# GD32A72_A74x register map
File version: 1.0
CPU: CM7 r2p1, little endian, MPU, FPU, DSP, 4 interrupt priority bits
Registers are 32-bit, read-write, reset 0x0 unless marked. A register's access mark holds for its fields unless they carry their own. Offsets are from the block's base; [hi:lo] are bit positions; {n}, {i} and the like mark numbered series; 'fields as' and 'values as' point back to an identical list.

## ENET_DMA — ENET_DMA DMA
Base 0x4000B000
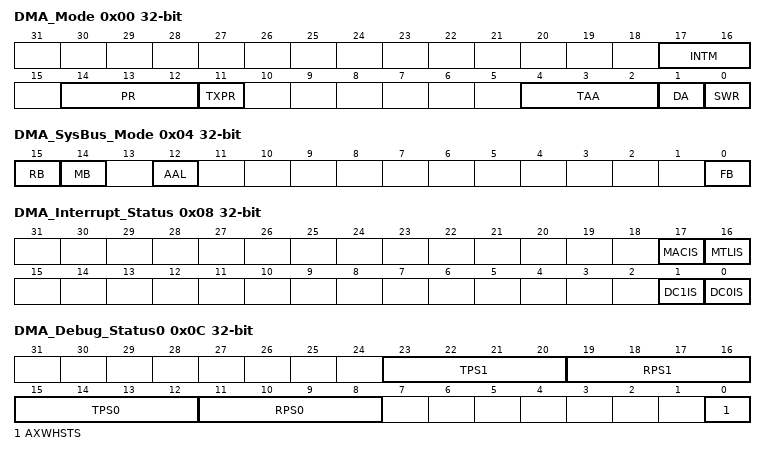
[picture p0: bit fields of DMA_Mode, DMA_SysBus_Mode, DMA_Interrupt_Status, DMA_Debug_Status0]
0x00 DMA_Mode
  [17:16] INTM — Interrupt Mode
    0=MODE0 (See above description); 1=MODE1 (See above description); 2=MODE2 (See above description)
  [14:12] PR — Priority Ratio
    {v}=R_{v+1}_1 (The priority ratio is {v+1}:1) (v=0..7)
  [11] TXPR — Transmit Priority
    0=DISABLE (Disabled); 1=ENABLE (Enabled)
  [4:2] TAA — Transmit Arbitration Algorithm
    0=FP (Fixed priority (Channel 0 has the lowest priority and the last channel has the highest priority)); 1=WSP (Weighted Strict Priority (WSP)); 2=WRR (Weighted Round-Robin (WRR))
  [1] DA — DMA Tx or Rx Arbitration Scheme
    0=WRR (Weighted Round-Robin with Rx:Tx or Tx:Rx); 1=FP (Fixed Priority)
  [0] SWR — Software Reset
    0=DISABLE (Disabled); 1=ENABLE (Enabled)
0x04 DMA_SysBus_Mode — DMA System Bus Mode
  [all] fields
    0=DISABLE (Disabled); 1=ENABLE (Enabled)
  [15] RB — Rebuild INCRx Burst
  [14] MB — Mixed Burst
  [12] AAL — Address-Aligned Beats
  [0] FB — Fixed Burst Length
0x08 DMA_Interrupt_Status ro
  [all] fields
    0=INACTIVE (Not detected); 1=ACTIVE (Detected)
  [17] MACIS — MAC Interrupt Status
  [16] MTLIS — MTL Interrupt Status
  [1] DC1IS — DMA Channel 1 Interrupt Status
  [0] DC0IS — DMA Channel 0 Interrupt Status
0x0C DMA_Debug_Status0 ro
  [23:20] TPS1 — DMA Channel 1 Transmit Process State
    0=STOP (Stopped (Reset or stop transmit command issued)); 1=RUN_FTTD (Running (Fetching transmit transfer descriptor)); 2=RUN_WS (Running (Waiting for status)); 3=RUN_RDS (Running (Reading data from system memory buffer and queuing it to the transmit buffer (Tx FIFO))); 4=TSTMP_WS (Timestamp write state); 6=SUSPND (Suspended (Transmit descriptor unavailable or transmit buffer underflow)); 7=RUN_CTD (Running (Closing transmit descriptor))
  [19:16] RPS1 — DMA Channel 1 Receive Process State
    0=STOP (Stopped (Reset or Stop receive command issued)); 1=RUN_FRTD (Running (Fetching receive transfer descriptor)); 3=RUN_WRP (Running (Waiting for receive packet)); 4=SUSPND (Suspended (Receive descriptor unavailable)); 5=RUN_CRD (Running (Closing the receive descriptor)); 6=TSTMP (Timestamp write state); 7=RUN_TRP (Running (Transferring the received packet data from the receive buffer to the system memory))
  [15:12] TPS0 — DMA Channel 0 Transmit Process State
    values as TPS1
  [11:8] RPS0 — DMA Channel 0 Receive Process State
    0=STOP (Stopped (Reset or stop receive command issued)); 1=RUN_FRTD (Running (Fetching receive transfer descriptor)); 3=RUN_WRP (Running (Waiting for receive packet)); 4=SUSPND (Suspended (Receive descriptor unavailable)); 5=RUN_CRD (Running (Closing the receive descriptor)); 6=TSTMP (Timestamp write state); 7=RUN_TRP (Running (Transferring the received packet data from the receive buffer to the system memory))
  [0] AXWHSTS — AHB Master Status
    0=INACTIVE (Not detected); 1=ACTIVE (detected)
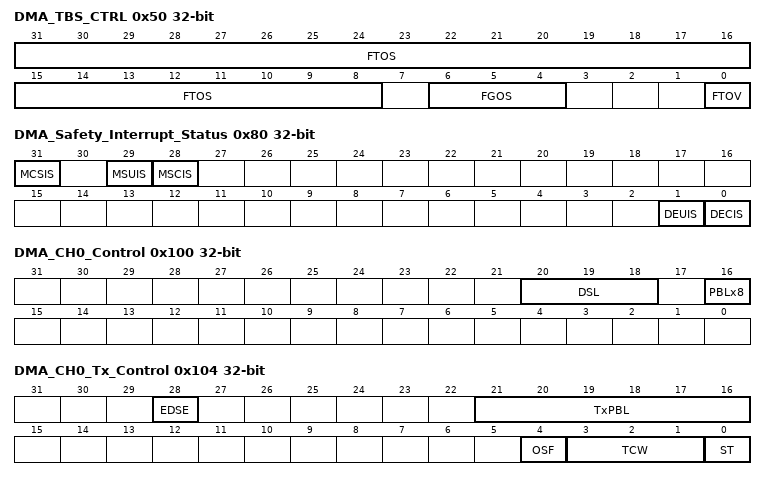
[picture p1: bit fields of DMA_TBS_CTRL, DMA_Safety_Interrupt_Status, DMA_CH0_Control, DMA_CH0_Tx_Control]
0x50 DMA_TBS_CTRL — DMA TBS Control
  [31:8] FTOS — Fetch Time Offset
  [6:4] FGOS — Fetch GSN Offset
  [0] FTOV — Fetch Time Offset Valid
    0=INVALID; 1=VALID
0x80 DMA_Safety_Interrupt_Status ro
  [all] fields
    0=INACTIVE (Not detected); 1=ACTIVE (Detected)
  [31] MCSIS — MAC Safety Uncorrectable Interrupt Status
  [29] MSUIS — MTL Safety Uncorrectable Error Interrupt Status
  [28] MSCIS — MTL Safety Correctable Error Interrupt Status
  [1] DEUIS — DMA ECC Uncorrectable Error Interrupt Status
  [0] DECIS — DMA ECC Correctable Error Interrupt Status
0x100 DMA_CH0_Control — DMA Channel 0 Control
  [20:18] DSL — Descriptor Skip Length
  [16] PBLx8 — 8xPBL mode
    0=DISABLE (Disabled); 1=ENABLE (Enabled)
0x104 DMA_CH0_Tx_Control — DMA Channel Tx Control
  [28] EDSE — Enhanced Descriptor Enable
    0=DISABLE (Disabled); 1=ENABLE (Enabled)
  [21:16] TxPBL — Transmit Programmable Burst Length
  [4] OSF — Operate on Second Packet
    0=DISABLE (Disabled); 1=ENABLE (Enabled)
  [3:1] TCW — Transmit Channel Weight
  [0] ST — Start or Stop Transmission Command
    0=STOP; 1=START
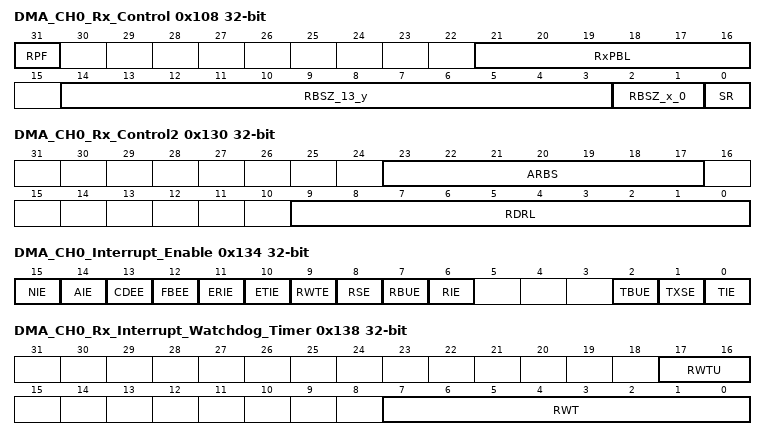
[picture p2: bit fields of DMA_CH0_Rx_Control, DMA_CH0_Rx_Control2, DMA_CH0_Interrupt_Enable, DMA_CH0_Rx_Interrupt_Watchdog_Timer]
0x108 DMA_CH0_Rx_Control — DMA Channel Rx Control
  [31] RPF — Rx Packet Flush
    0=DISABLE (Disabled); 1=ENABLE (Enabled)
  [21:16] RxPBL — Receive Programmable Burst Length
  [14:3] RBSZ_13_y — Receive Buffer size High
  [2:1] RBSZ_x_0 ro — Receive Buffer size Low
  [0] SR — Start or Stop Receive
    0=STOP; 1=START
0x114 DMA_CH0_TxDesc_Address — DMA Channel 0 Tx Descriptor List Address
  [31:2] TDESLA — Start of Transmit List
0x11C DMA_CH0_RxDesc_Address — DMA Channel 0 Rx Descriptor List Address
  [31:2] RDESLA — Start of Receive List
0x120 DMA_CH0_TxDesc_Tail_Pointer — DMA Channel 0 Tx Descriptor Tail Pointer
  [31:2] TDTP — Transmit Descriptor Tail Pointer
0x128 DMA_CH0_RxDesc_Tail_Pointer — DMA Channeli 0 Rx Descriptor List Pointer
  [31:2] RDTP — Receive Descriptor Tail Pointer
0x12C DMA_CH0_TxDesc_Ring_Length — DMA Channel 0 Tx Descriptor Ring Length
  [9:0] TDRL — Transmit Descriptor Ring Length
0x130 DMA_CH0_Rx_Control2 — DMA channel receive control 2 register
  [23:17] ARBS — Alternate Receive Buffer Size
  [9:0] RDRL — Receive Descriptor Ring Length
0x134 DMA_CH0_Interrupt_Enable — DMA Channel 0 Interrupt Enable
  [all] fields
    0=DISABLE; 1=ENABLE
  [15] NIE — Normal Interrupt Summary Enable
  [14] AIE — Abnormal Interrupt Summary Enable
  [13] CDEE — Context Descriptor Error Enable
  [12] FBEE — Fatal Bus Error Enable
  [11] ERIE — Early Receive Interrupt Enable
  [10] ETIE — Early Transmit Interrupt Enable
  [9] RWTE — Receive Watchdog Timeout Enable
  [8] RSE — Receive Stopped Enable
  [7] RBUE — Receive Buffer Unavailable Enable
  [6] RIE — Receive Interrupt Enable
  [2] TBUE — Transmit Buffer Unavailable Enable
  [1] TXSE — Transmit Stopped Enable
  [0] TIE — Transmit Interrupt Enable
0x138 DMA_CH0_Rx_Interrupt_Watchdog_Timer — DMA Channel 0 Rx Interrupt Watchdog Timer
  [17:16] RWTU — Receive Interrupt Watchdog Timer Count Units
  [7:0] RWT — Receive Interrupt Watchdog Timer Count
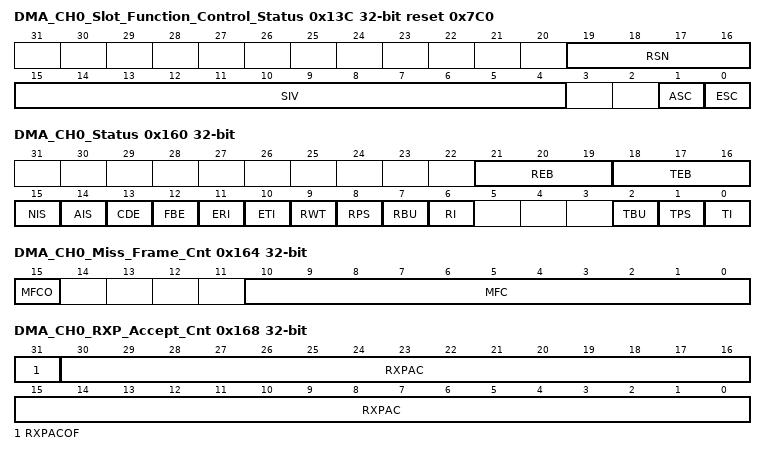
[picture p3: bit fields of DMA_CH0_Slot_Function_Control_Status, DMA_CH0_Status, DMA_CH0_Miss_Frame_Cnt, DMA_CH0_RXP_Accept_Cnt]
0x13C DMA_CH0_Slot_Function_Control_Status reset 0x7C0 — DMA Channel 0 Slot Function Control Status
  [19:16] RSN ro — Reference Slot Number
  [15:4] SIV — Slot Interval Value
  [1] ASC — Advance Slot Check
    0=DISABLE (Disabled); 1=ENABLE (Enabled)
  [0] ESC — Enable Slot Comparison
    0=DISABLE (Disabled); 1=ENABLE (Enabled)
0x144 DMA_CH0_Current_App_TxDesc ro — DMA Channel 0 Current Application Transmit Descriptor
  [31:0] CURTDESAPTR — Application Transmit Descriptor Address Pointer
0x14C DMA_CH0_Current_App_RxDesc ro — DMA Channel 0 Current Application Receive Descriptor
  [31:0] CURRDESAPTR — Application Receive Descriptor Address Pointer
0x154 DMA_CH0_Current_App_TxBuffer ro — DMA Channel 0 Current Application Transmit Descriptor
  [31:0] CURTBUFAPTR — Application Transmit Buffer Address Pointer
0x160 DMA_CH0_Status — DMA Channel 0 Status
  [21:19] REB ro — Rx DMA Error Bits
  [18:16] TEB ro — Tx DMA Error Bits
  [15] NIS — Normal Interrupt Summary
    0=INACTIVE (Not detected); 1=ACTIVE (Detected)
  [14] AIS — Abnormal Interrupt Summary
    0=INACTIVE (Not detected); 1=ACTIVE (Detected)
  [13] CDE — Context Descriptor Error
    0=INACTIVE (Not detected); 1=ACTIVE (Detected)
  [12] FBE — Fatal Bus Error
    0=INACTIVE (Not detected); 1=ACTIVE (Detected)
  [11] ERI — Early Receive Interrupt
    0=INACTIVE (Not detected); 1=ACTIVE (Detected)
  [10] ETI — Early Transmit Interrupt
    0=INACTIVE (Not detected); 1=ACTIVE (Detected)
  [9] RWT — Receive Watchdog Timeout
    0=INACTIVE (Not detected); 1=ACTIVE (Detected)
  [8] RPS — Receive Process Stopped
    0=INACTIVE (Not detected); 1=ACTIVE (Detected)
  [7] RBU — Receive Buffer Unavailable
    0=INACTIVE (Not detected); 1=ACTIVE (Detected)
  [6] RI — Receive Interrupt
    0=INACTIVE (Not detected); 1=ACTIVE (Detected)
  [2] TBU — Transmit Buffer Unavailable
    0=INACTIVE (Not detected); 1=ACTIVE (Detected)
  [1] TPS — Transmit Process Stopped
    0=INACTIVE (Not detected); 1=ACTIVE (Detected)
  [0] TI — Transmit Interrupt
    0=INACTIVE (Not detected); 1=ACTIVE (Detected)
0x164 DMA_CH0_Miss_Frame_Cnt ro — DMA Channel 0 Miss Frame Counter
  [15] MFCO — Overflow status of the MFC Counter
    0=INACTIVE (Not occurred); 1=ACTIVE (Occurred)
  [10:0] MFC — Dropped Packet Counters Indicates the number of packet counters that DMA drops either because of bus error or because of programing RPF field in DMA_CH${i}_Rx_Control register
0x168 DMA_CH0_RXP_Accept_Cnt ro — DMA Channel 0 Rx Parser Accept Count
  [31] RXPACOF — Rx Parser Accept Counter Overflow Bit
    0=INACTIVE (Not occurred); 1=ACTIVE (Occurred)
  [30:0] RXPAC — Rx Parser Accept Counter
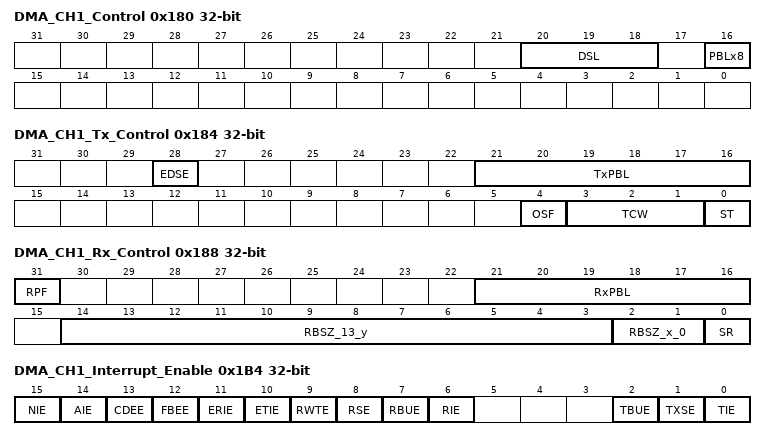
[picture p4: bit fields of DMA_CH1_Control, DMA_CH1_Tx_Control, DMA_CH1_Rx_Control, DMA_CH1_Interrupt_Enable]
0x180 DMA_CH1_Control — DMA Channel 1 Control
  fields as DMA_CH0_Control
0x184 DMA_CH1_Tx_Control — DMA Channel 1 Tx Control
  fields as DMA_CH0_Tx_Control
0x188 DMA_CH1_Rx_Control — DMA Channel 1 Rx Control
  fields as DMA_CH0_Rx_Control
0x194 DMA_CH1_TxDesc_Address — DMA Channel 1 Tx Descriptor List Address
  [31:2] TDESLA — Start of Transmit List
0x19C DMA_CH1_RxDesc_Address — DMA Channel 1 Rx Descriptor List Address
  [31:2] RDESLA — Start of Receive List
0x1A0 DMA_CH1_TxDesc_Tail_Pointer — DMA Channel 1 Tx Descriptor Tail Pointer
  [31:2] TDTP — Transmit Descriptor Tail Pointer
0x1A8 DMA_CH1_RxDesc_Tail_Pointer — DMA Channel 1 Rx Descriptor Tail Pointer
  [31:2] RDTP — Receive Descriptor Tail Pointer
0x1AC DMA_CH1_TxDesc_Ring_Length — DMA Channel 1 Tx Descriptor Ring Length
  [9:0] TDRL — Transmit Descriptor Ring Length
0x1B0 DMA_CH1_RxDesc_Ring_Length — DMA Channel 1 Rx Descriptor Ring Length
  [9:0] RDRL — Receive Descriptor Ring Length
0x1B4 DMA_CH1_Interrupt_Enable — DMA Channel 1 Interrupt Enable
  fields as DMA_CH0_Interrupt_Enable
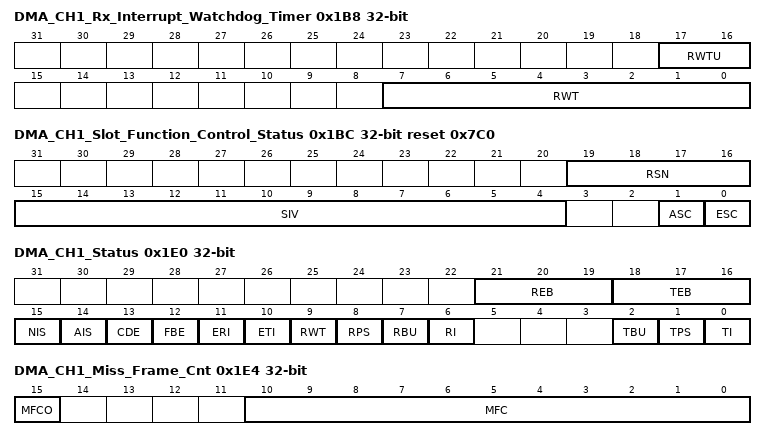
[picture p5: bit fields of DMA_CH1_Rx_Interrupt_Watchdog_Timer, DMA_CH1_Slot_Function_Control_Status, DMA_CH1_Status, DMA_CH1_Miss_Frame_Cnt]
0x1B8 DMA_CH1_Rx_Interrupt_Watchdog_Timer — DMA Channel 1 Rx Interrupt Watchdog Timer
  fields as DMA_CH0_Rx_Interrupt_Watchdog_Timer
0x1BC DMA_CH1_Slot_Function_Control_Status reset 0x7C0 — DMA Channel 1 Slot Function Control Status
  [19:16] RSN ro — Reference Slot Number
  [15:4] SIV — Slot Interval Value
  [1] ASC — Advance Slot Check
    0=DISABLE (Disabled); 1=ENABLE (Enabled)
  [0] ESC — Enable Slot Comparison
    0=DISABLE; 1=ENABLE
0x1C4 DMA_CH1_Current_App_TxDesc ro — DMA Channel 1 Current Application Transmit Descriptor
  [31:0] CURTDESAPTR — Application Transmit Descriptor Address Pointer
0x1CC DMA_CH1_Current_App_RxDesc ro — DMA Channel 1 Current Application Receive Descriptor
  [31:0] CURRDESAPTR — Application Receive Descriptor Address Pointer
0x1D4 DMA_CH1_Current_App_TxBuffer ro — DMA Channel 1 Current Application Transmit Buffer
  [31:0] CURTBUFAPTR — Application Transmit Buffer Address Pointer
0x1DC DMA_CH1_Current_App_RxBuffer ro — DMA Channel 1 Current Application Receive Buffer
  [31:0] CURRBUFAPTR — Application Receive Buffer Address Pointer
0x1E0 DMA_CH1_Status — DMA Channel 1 Status
  fields as DMA_CH0_Status
0x1E4 DMA_CH1_Miss_Frame_Cnt ro — DMA Channel 1 Miss Frame Counter
  [15] MFCO — Overflow status of the MFC Counter
    0=INACTIVE (Not occurred); 1=ACTIVE (Occurred)
  [10:0] MFC — Dropped Packet Counters
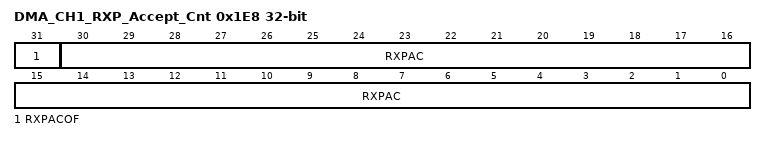
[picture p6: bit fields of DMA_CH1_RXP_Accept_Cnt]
0x1E8 DMA_CH1_RXP_Accept_Cnt ro — DMA Channel 1 Rx Parser Accept Count
  fields as DMA_CH0_RXP_Accept_Cnt
